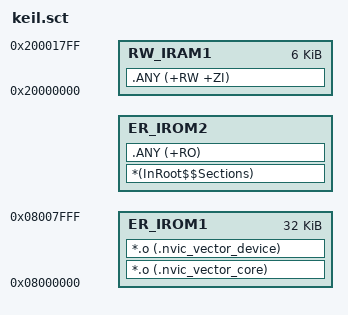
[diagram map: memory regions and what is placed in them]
LR_IROM1 0x0800000 0x8000 {
    ER_IROM1 0x08000000 0x8000 {
     *.o (.nvic_vector_core)
     *.o (.nvic_vector_device)
    }
    ER_IROM2 +0 {
      *(InRoot$$Sections)
      .ANY (+RO)
    }
    RW_IRAM1 0x20000000 0x1800 {
      .ANY (+RW +ZI)
    }
}
